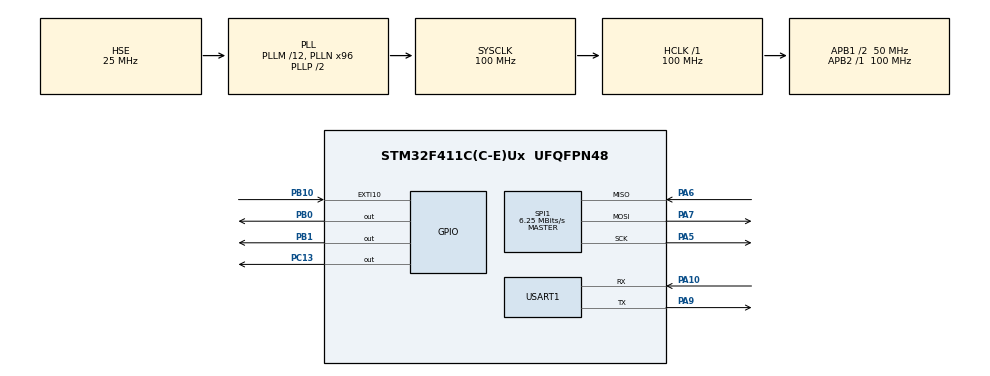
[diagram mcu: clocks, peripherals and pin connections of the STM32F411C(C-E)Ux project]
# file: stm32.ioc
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FREERTOS.Tasks01=AppTask,24,512,StartAppTask,Default,NULL,Dynamic,NULL,NULL
FREERTOS.configCHECK_FOR_STACK_OVERFLOW=2
Mcu.Family=STM32F4
Mcu.Name=STM32F411C(C-E)Ux
Mcu.Package=UFQFPN48
NVIC.EXTI15_10_IRQn=true\:5\:0\:false\:false\:true\:true\:true\:true\:true
NVIC.PriorityGroup=NVIC_PRIORITYGROUP_4
NVIC.TIM1_TRG_COM_TIM11_IRQn=true\:15\:0\:false\:false\:true\:false\:false\:true\:true
NVIC.TimeBase=TIM1_TRG_COM_TIM11_IRQn
NVIC.TimeBaseIP=TIM11
PA10.Mode=Asynchronous
PA10.Signal=USART1_RX
PA13.Mode=Serial_Wire
PA13.Signal=SYS_JTMS-SWDIO
PA14.Mode=Serial_Wire
PA14.Signal=SYS_JTCK-SWCLK
PA5.Mode=Full_Duplex_Master
PA5.Signal=SPI1_SCK
PA6.Mode=Full_Duplex_Master
PA6.Signal=SPI1_MISO
PA7.Mode=Full_Duplex_Master
PA7.Signal=SPI1_MOSI
PA9.Mode=Asynchronous
PA9.Signal=USART1_TX
PB0.Signal=GPIO_Output
PB1.Signal=GPIO_Output
PB10.GPIO_ModeDefaultEXTI=GPIO_MODE_IT_FALLING
PB10.GPIO_PuPd=GPIO_PULLUP
PB10.Signal=GPXTI10
PC13-ANTI_TAMP.Signal=GPIO_Output
PH0\ -\ OSC_IN.Mode=HSE-External-Oscillator
PH0\ -\ OSC_IN.Signal=RCC_OSC_IN
PH1\ -\ OSC_OUT.Mode=HSE-External-Oscillator
PH1\ -\ OSC_OUT.Signal=RCC_OSC_OUT
ProjectManager.HeapSize=0x200
ProjectManager.StackSize=0x400
ProjectManager.TargetToolchain=CMake
RCC.48MHZClocksFreq_Value=50000000
RCC.AHBFreq_Value=100000000
RCC.APB1CLKDivider=RCC_HCLK_DIV2
RCC.APB1Freq_Value=50000000
RCC.APB1TimFreq_Value=100000000
RCC.APB2Freq_Value=100000000
RCC.APB2TimFreq_Value=100000000
RCC.CortexFreq_Value=100000000
RCC.HCLKFreq_Value=100000000
RCC.HSE_VALUE=25000000
RCC.HSI_VALUE=16000000
RCC.LSE_VALUE=32768
RCC.PLLM=12
RCC.PLLN=96
RCC.PLLSourceVirtual=RCC_PLLSOURCE_HSE
RCC.SYSCLKFreq_VALUE=100000000
RCC.SYSCLKSource=RCC_SYSCLKSOURCE_PLLCLK
RCC.VCOOutputFreq_Value=200000000
SPI1.BaudRatePrescaler=SPI_BAUDRATEPRESCALER_16
SPI1.CalculateBaudRate=6.25 MBits/s
SPI1.Direction=SPI_DIRECTION_2LINES
SPI1.Mode=SPI_MODE_MASTER
SPI1.VirtualType=VM_MASTER
USART1.VirtualMode=VM_ASYNC
VP_FREERTOS_VS_CMSIS_V2.Mode=CMSIS_V2
VP_SYS_VS_tim11.Mode=TIM11
board=custom

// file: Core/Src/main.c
/* USER CODE BEGIN Header */
/**
  ******************************************************************************
  * @file           : main.c
  * @brief          : Main program body
  ******************************************************************************
  * @attention
  *
  * Copyright (c) 2026 STMicroelectronics.
  * All rights reserved.
  *
  * This software is licensed under terms that can be found in the LICENSE file
  * in the root directory of this software component.
  * If no LICENSE file comes with this software, it is provided AS-IS.
  *
  ******************************************************************************
  */
/* USER CODE END Header */
#include "main.h"
#include "cmsis_os.h"

SPI_HandleTypeDef hspi1;

UART_HandleTypeDef huart1;

/* Definitions for AppTask */
osThreadId_t AppTaskHandle;
const osThreadAttr_t AppTask_attributes = {
  .name = "AppTask",
  .stack_size = 512 * 4,
  .priority = (osPriority_t) osPriorityNormal,
};
/* USER CODE BEGIN PV */
osThreadId_t RadioTaskHandle;
const osThreadAttr_t RadioTask_attributes = {
  .name = "RadioTask",
  .stack_size = 512 * 4,
  .priority = (osPriority_t) osPriorityNormal,
};
/* USER CODE END PV */

void SystemClock_Config(void);
static void MX_GPIO_Init(void);
static void MX_SPI1_Init(void);
static void MX_USART1_UART_Init(void);
void StartAppTask(void *argument);

/* USER CODE BEGIN PFP */
extern void RadioTask(void* argument);
/* USER CODE END PFP */

int main(void)
{

  /* MCU Configuration--------------------------------------------------------*/

  /* Reset of all peripherals, Initializes the Flash interface and the Systick. */
  HAL_Init();

  /* Configure the system clock */
  SystemClock_Config();

  /* Initialize all configured peripherals */
  MX_GPIO_Init();
  MX_SPI1_Init();
  MX_USART1_UART_Init();

  /* Init scheduler */
  osKernelInitialize();

  /* Create the thread(s) */
  /* creation of AppTask */
  AppTaskHandle = osThreadNew(StartAppTask, NULL, &AppTask_attributes);

  /* USER CODE BEGIN RTOS_THREADS */
  /* add threads, ... */
  RadioTaskHandle = osThreadNew(RadioTask, NULL, &RadioTask_attributes);
  /* USER CODE END RTOS_THREADS */

  /* Start scheduler */
  osKernelStart();

  /* We should never get here as control is now taken by the scheduler */

  /* Infinite loop */
  while (1)
  {

  }
}

void SystemClock_Config(void)
{
  RCC_OscInitTypeDef RCC_OscInitStruct = {0};
  RCC_ClkInitTypeDef RCC_ClkInitStruct = {0};

  /** Configure the main internal regulator output voltage
  */
  __HAL_RCC_PWR_CLK_ENABLE();
  __HAL_PWR_VOLTAGESCALING_CONFIG(PWR_REGULATOR_VOLTAGE_SCALE1);

  /** Initializes the RCC Oscillators according to the specified parameters
  * in the RCC_OscInitTypeDef structure.
  */
  RCC_OscInitStruct.OscillatorType = RCC_OSCILLATORTYPE_HSE;
  RCC_OscInitStruct.HSEState = RCC_HSE_ON;
  RCC_OscInitStruct.PLL.PLLState = RCC_PLL_ON;
  RCC_OscInitStruct.PLL.PLLSource = RCC_PLLSOURCE_HSE;
  RCC_OscInitStruct.PLL.PLLM = 12;
  RCC_OscInitStruct.PLL.PLLN = 96;
  RCC_OscInitStruct.PLL.PLLP = RCC_PLLP_DIV2;
  RCC_OscInitStruct.PLL.PLLQ = 4;
  if (HAL_RCC_OscConfig(&RCC_OscInitStruct) != HAL_OK)
  {
    Error_Handler();
  }

  /** Initializes the CPU, AHB and APB buses clocks
  */
  RCC_ClkInitStruct.ClockType = RCC_CLOCKTYPE_HCLK|RCC_CLOCKTYPE_SYSCLK
                              |RCC_CLOCKTYPE_PCLK1|RCC_CLOCKTYPE_PCLK2;
  RCC_ClkInitStruct.SYSCLKSource = RCC_SYSCLKSOURCE_PLLCLK;
  RCC_ClkInitStruct.AHBCLKDivider = RCC_SYSCLK_DIV1;
  RCC_ClkInitStruct.APB1CLKDivider = RCC_HCLK_DIV2;
  RCC_ClkInitStruct.APB2CLKDivider = RCC_HCLK_DIV1;

  if (HAL_RCC_ClockConfig(&RCC_ClkInitStruct, FLASH_LATENCY_3) != HAL_OK)
  {
    Error_Handler();
  }
}

static void MX_SPI1_Init(void)
{

  /* SPI1 parameter configuration*/
  hspi1.Instance = SPI1;
  hspi1.Init.Mode = SPI_MODE_MASTER;
  hspi1.Init.Direction = SPI_DIRECTION_2LINES;
  hspi1.Init.DataSize = SPI_DATASIZE_8BIT;
  hspi1.Init.CLKPolarity = SPI_POLARITY_LOW;
  hspi1.Init.CLKPhase = SPI_PHASE_1EDGE;
  hspi1.Init.NSS = SPI_NSS_SOFT;
  hspi1.Init.BaudRatePrescaler = SPI_BAUDRATEPRESCALER_16;
  hspi1.Init.FirstBit = SPI_FIRSTBIT_MSB;
  hspi1.Init.TIMode = SPI_TIMODE_DISABLE;
  hspi1.Init.CRCCalculation = SPI_CRCCALCULATION_DISABLE;
  hspi1.Init.CRCPolynomial = 10;
  if (HAL_SPI_Init(&hspi1) != HAL_OK)
  {
    Error_Handler();
  }

}

static void MX_USART1_UART_Init(void)
{

  huart1.Instance = USART1;
  huart1.Init.BaudRate = 115200;
  huart1.Init.WordLength = UART_WORDLENGTH_8B;
  huart1.Init.StopBits = UART_STOPBITS_1;
  huart1.Init.Parity = UART_PARITY_NONE;
  huart1.Init.Mode = UART_MODE_TX_RX;
  huart1.Init.HwFlowCtl = UART_HWCONTROL_NONE;
  huart1.Init.OverSampling = UART_OVERSAMPLING_16;
  if (HAL_UART_Init(&huart1) != HAL_OK)
  {
    Error_Handler();
  }

}

static void MX_GPIO_Init(void)
{
  GPIO_InitTypeDef GPIO_InitStruct = {0};

  /* GPIO Ports Clock Enable */
  __HAL_RCC_GPIOC_CLK_ENABLE();
  __HAL_RCC_GPIOH_CLK_ENABLE();
  __HAL_RCC_GPIOA_CLK_ENABLE();
  __HAL_RCC_GPIOB_CLK_ENABLE();

  /*Configure GPIO pin Output Level */
  HAL_GPIO_WritePin(GPIOC, GPIO_PIN_13, GPIO_PIN_RESET);

  /*Configure GPIO pin Output Level */
  HAL_GPIO_WritePin(GPIOB, GPIO_PIN_0|GPIO_PIN_1, GPIO_PIN_RESET);

  /*Configure GPIO pin : PC13 */
  GPIO_InitStruct.Pin = GPIO_PIN_13;
  GPIO_InitStruct.Mode = GPIO_MODE_OUTPUT_PP;
  GPIO_InitStruct.Pull = GPIO_NOPULL;
  GPIO_InitStruct.Speed = GPIO_SPEED_FREQ_LOW;
  HAL_GPIO_Init(GPIOC, &GPIO_InitStruct);

  /*Configure GPIO pins : PB0 PB1 */
  GPIO_InitStruct.Pin = GPIO_PIN_0|GPIO_PIN_1;
  GPIO_InitStruct.Mode = GPIO_MODE_OUTPUT_PP;
  GPIO_InitStruct.Pull = GPIO_NOPULL;
  GPIO_InitStruct.Speed = GPIO_SPEED_FREQ_LOW;
  HAL_GPIO_Init(GPIOB, &GPIO_InitStruct);

  /*Configure GPIO pin : PB10 */
  GPIO_InitStruct.Pin = GPIO_PIN_10;
  GPIO_InitStruct.Mode = GPIO_MODE_IT_FALLING;
  GPIO_InitStruct.Pull = GPIO_PULLUP;
  HAL_GPIO_Init(GPIOB, &GPIO_InitStruct);

  /* EXTI interrupt init*/
  HAL_NVIC_SetPriority(EXTI15_10_IRQn, 5, 0);
  HAL_NVIC_EnableIRQ(EXTI15_10_IRQn);

}

void StartAppTask(void *argument)
{
  /* USER CODE BEGIN 5 */
  /* Infinite loop */
  (void)argument;
  extern void app_main(void);
  app_main();
  /* USER CODE END 5 */
}

void HAL_TIM_PeriodElapsedCallback(TIM_HandleTypeDef *htim)
{
  if (htim->Instance == TIM11)
  {
    HAL_IncTick();
  }
}

void Error_Handler(void)
{
  __disable_irq();
  while (1)
  {
  }
}

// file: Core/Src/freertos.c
/* USER CODE BEGIN Header */
/**
  ******************************************************************************
  * File Name          : freertos.c
  * Description        : Code for freertos applications
  ******************************************************************************
  * @attention
  *
  * Copyright (c) 2026 STMicroelectronics.
  * All rights reserved.
  *
  * This software is licensed under terms that can be found in the LICENSE file
  * in the root directory of this software component.
  * If no LICENSE file comes with this software, it is provided AS-IS.
  *
  ******************************************************************************
  */
/* USER CODE END Header */

#include "FreeRTOS.h"
#include "task.h"
#include "main.h"

/* Hook prototypes */
void vApplicationStackOverflowHook(xTaskHandle xTask, signed char *pcTaskName);

/* USER CODE BEGIN 4 */
void vApplicationStackOverflowHook(xTaskHandle xTask, signed char *pcTaskName)
{
   /* Run time stack overflow checking is performed if
   configCHECK_FOR_STACK_OVERFLOW is defined to 1 or 2. This hook function is
   called if a stack overflow is detected. */
  (void)xTask;
  while (1)
  {
      HAL_GPIO_TogglePin(GPIOC, GPIO_PIN_13);
      for (volatile int i = 0; i < 500000; i++);
  }
}
/* USER CODE END 4 */
